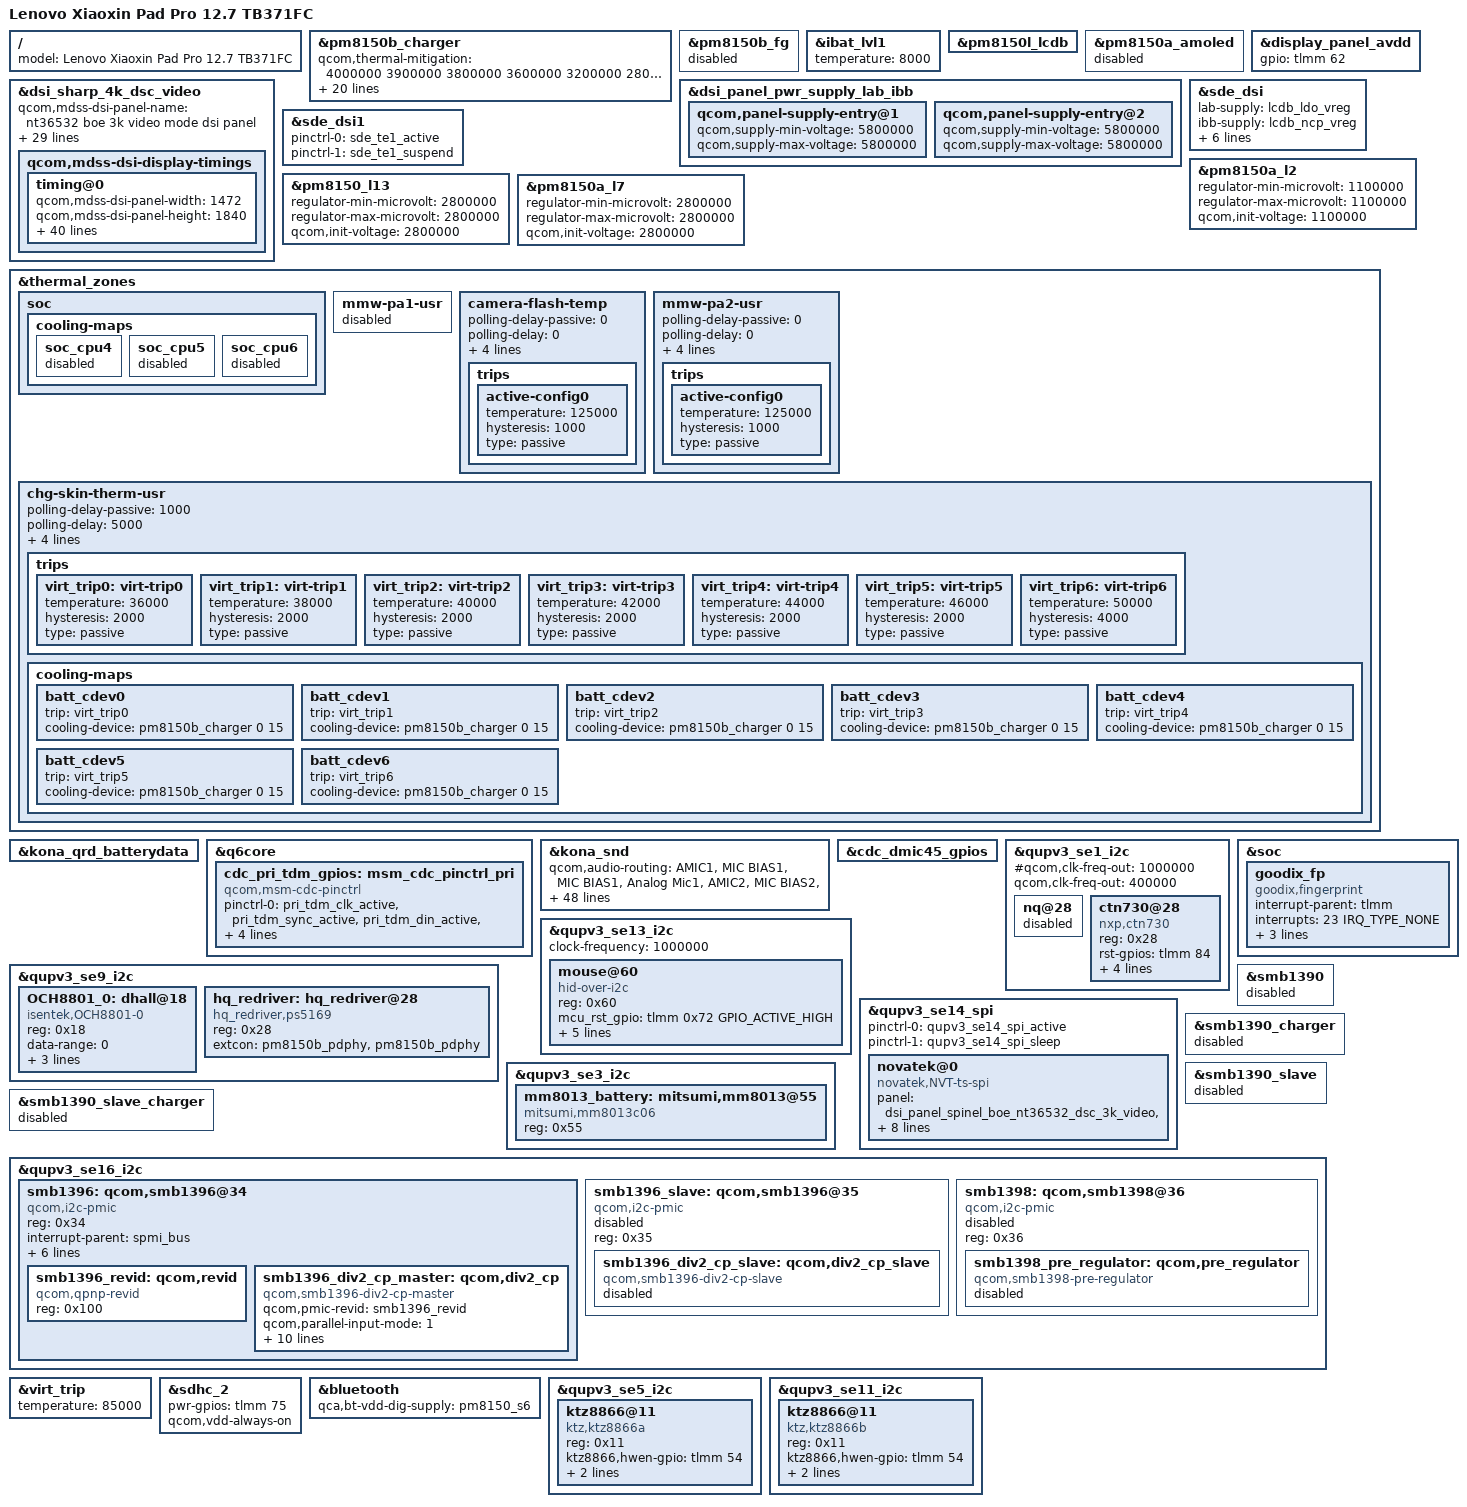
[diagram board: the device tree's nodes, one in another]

#include "kona-hdk-overlay.dts"

/ {
	model = "Lenovo Xiaoxin Pad Pro 12.7 TB371FC";
};

&pm8150b_charger {
	/delete-property/ qcom,sw-jeita-enable;
	/delete-property/ qcom,suspend-input-on-debug-batt;
	/delete-property/ qcom,fcc-stepping-enable;

	device_type = "battery";
	qcom,thermal-mitigation = <4000000 3900000 3800000 3600000 3200000 2800000 2400000 2000000 1800000 1600000 1400000 1200000 1000000 800000 600000 500000>;

	/delete-property/ qcom,auto-recharge-soc;
	qcom,auto-recharge-vbat-mv = <4380>;

	io-channels = <&pm8150b_vadc ADC_MID_CHG_DIV6>,
			 <&pm8150b_vadc ADC_USB_IN_I>,
			 <&pm8150b_vadc ADC_AMUX_THM3_PU2>,
			 <&pm8150b_vadc ADC_SBUx>,
			 <&pm8150b_vadc ADC_VPH_PWR>,
			 <&pm8150b_vadc ADC_CHG_TEMP>;
	io-channel-names = "mid_voltage", "usb_in_current", "conn_temp", "sbux_res", "vph_voltage", "chg_temp";

	qcom,pd-thermal-mitigation = <6000000 5450000 5300000 5000000 4600000 4200000 3800000 3400000 3200000 3000000 2800000 2600000 2400000 2400000 2200000 2100000>;
	qcom,chg-control-gpio = <&pm8150_gpios 10 GPIO_ACTIVE_HIGH>;
	lenovo,jeita_enable = <1>;
	qcom,fv-max-uv = <4490000>;
	qcom,fcc-max-ua = <6000000>;
	qcom,max-voltage-uv = <4490000>;
	qcom,fastchg-current-ma = <6000>;
	qcom,jeita-fcc-ranges = <0 150 3000000>,
			 <150 450 3000000>,
			 <450 500 3000000>;
	qcom,jeita-fv-ranges = <0 500 4450000>;
	qcom,otg-cl-ua = <1800000>;
	qcom,hvdcp2-max-icl-ua = <2000000>;
};

&pm8150b_fg {
	status = "disabled";
};

&ibat_lvl1 {
	temperature = <8000>;
};

&pm8150l_lcdb {
	status = "ok";
};

&pm8150a_amoled {
	status = "disabled";
};

&dsi_sharp_4k_dsc_video {
	/delete-property/ qcom,adjust-timer-wakeup-ms;
	/delete-property/ qcom,mdss-dsi-panel-hdr-enabled;
	/delete-property/ qcom,mdss-dsi-panel-hdr-color-primaries;
	/delete-property/ qcom,mdss-dsi-panel-peak-brightness;
	/delete-property/ qcom,mdss-dsi-panel-blackness-level;

	qcom,mdss-dsi-panel-name = "nt36532 boe 3k video mode dsi panel";
	qcom,mdss-dsi-lp11-init;
	qcom,mdss-dsi-underflow-color = <0xff>;
	qcom,mdss-dsi-reset-sequence = <1 10>, <0 10>, <1 10>, <0 10>, <1 10>;
	qcom,mdss-pan-physical-width-dimension = <274>;
	qcom,mdss-pan-physical-height-dimension = <171>;
	qcom,mdss-dsi-rx-eot-ignore;
	qcom,cmd-sync-wait-broadcast;
	qcom,mdss-dsi-panel-broadcast-mode;
	qcom,mdss-dsi-pan-enable-dynamic-fps;
	qcom,mdss-dsi-pan-fps-update = "dfps_immediate_porch_mode_vfp";
	qcom,dsi-supported-dfps-list = <30 60 120>;
	qcom,mdss-dsi-panel-count = <2>;
	qcom,ulps-enabled;
	qcom,esd-check-enabled;
	qcom,dsi-ctrl-num = <0 1>;
	qcom,dsi-phy-num = <0 1>;
	qcom,mdss-dsi-panel-status-check-mode = "te_signal_check";
	qcom,panel-supply-entries = <&dsi_panel_pwr_supply_lab_ibb>;
	qcom,mdss-dsi-bl-pmic-control-type = "bl_ctrl_external";
	qcom,mdss-dsi-bl-min-level = <1>;
	qcom,mdss-dsi-bl-max-level = <2047>;
	qcom,mdss-brightness-max-level = <2047>;
	qcom,platform-reset-gpio = <&tlmm 69 GPIO_ACTIVE_HIGH>;
	qcom,platform-te-gpio = <&tlmm 66 GPIO_ACTIVE_HIGH>;

	qcom,mdss-dsi-display-timings {
		timing@0 {
			qcom,mdss-dsi-panel-width = <1472>;
			qcom,mdss-dsi-panel-height = <1840>;
			qcom,mdss-dsi-h-front-porch = <201>;
			qcom,mdss-dsi-h-back-porch = <60>;
			qcom,mdss-dsi-h-pulse-width = <12>;
			qcom,mdss-dsi-v-back-porch = <182>;
			qcom,mdss-dsi-v-front-porch = <26>;
			qcom,mdss-dsi-v-pulse-width = <2>;
			qcom,mdss-dsi-panel-framerate = <120>;
			qcom,mdss-dsi-h-left-border = <0>;
			qcom,mdss-dsi-h-right-border = <0>;
			qcom,mdss-dsi-v-top-border = <0>;
			qcom,mdss-dsi-v-bottom-border = <0>;
			qcom,mdss-dsi-panel-clockrate = <1130000000>;
			qcom,mdss-dsi-on-command = [
				39 01 00 00 00 00 02 ff 20
				39 01 00 00 00 00 02 fb 01
				39 01 00 00 00 00 02 30 00
				39 01 00 00 00 00 02 ff 10
				39 01 00 00 00 00 02 fb 01
				39 01 00 00 00 00 07 3b 03 b8 1a 0a 0a 00
				39 01 00 00 00 00 02 ff 27
				39 01 00 00 00 00 02 fb 01
				39 01 00 00 00 00 02 d0 31
				39 01 00 00 00 00 02 d1 84
				39 01 00 00 00 00 02 d2 38
				39 01 00 00 00 00 02 ff 10
				39 01 00 00 00 00 02 fb 01
				39 01 00 00 00 00 02 35 00
				05 01 00 00 78 00 02 11 00
				05 01 00 00 64 00 02 29 00
			];
			qcom,mdss-dsi-off-command = [
				05 01 00 00 00 00 02 28 00
				05 01 00 00 3c 00 02 10 00
			];
			qcom,mdss-dsi-on-command-state = "dsi_lp_mode";
			qcom,mdss-dsi-off-command-state = "dsi_lp_mode";
			qcom,mdss-dsc-version = <17>;
			qcom,mdss-dsc-scr-version = <0>;
			qcom,mdss-dsc-slice-height = <20>;
			qcom,mdss-dsc-slice-width = <736>;
			qcom,mdss-dsi-dispparam-pen-144hz-command = [
				39 00 00 00 00 00 02 ff 10
				39 00 00 00 00 00 02 fb 01
				39 01 00 00 00 00 02 b3 00
			];
			qcom,mdss-dsi-dispparam-pen-120hz-command = [
				39 00 00 00 00 00 02 ff 10
				39 00 00 00 00 00 02 fb 01
				39 01 00 00 00 00 02 b3 40
			];
			qcom,mdss-dsi-dispparam-pen-60hz-command = [
				39 00 00 00 00 00 02 ff 10
				39 00 00 00 00 00 02 fb 01
				39 01 00 00 00 00 02 b3 40
			];
			qcom,mdss-dsi-dispparam-pen-30hz-command = [
				39 00 00 00 00 00 02 ff 10
				39 00 00 00 00 00 02 fb 01
				39 01 00 00 00 00 02 b3 40
			];
			qcom,mdss-dsi-dispparam-pen-144hz-command-state = "dsi_lp_mode";
			qcom,mdss-dsi-dispparam-pen-120hz-command-state = "dsi_lp_mode";
			qcom,mdss-dsi-dispparam-pen-60hz-command-state = "dsi_lp_mode";
			qcom,mdss-dsi-dispparam-pen-30hz-command-state = "dsi_lp_mode";
			qcom,mdss-dsi-panel-phy-timings = [
				00 25 0a 0a 1b 18 0a
				0a 0a 02 04 00 1f 0f
			];
		};
	};
};

&dsi_panel_pwr_supply_lab_ibb {
	qcom,panel-supply-entry@1 {
		qcom,supply-min-voltage = <5800000>;
		qcom,supply-max-voltage = <5800000>;
	};

	qcom,panel-supply-entry@2 {
		qcom,supply-min-voltage = <5800000>;
		qcom,supply-max-voltage = <5800000>;
	};
};

&display_panel_avdd {
	gpio = <&tlmm 62 0x00>;
	/delete-property/ pinctrl-names;
	/delete-property/ pinctrl-0;
};

&sde_dsi {
	lab-supply = <&lcdb_ldo_vreg>;
	ibb-supply = <&lcdb_ncp_vreg>;
	/delete-property/ vddio-supply;
	/delete-property/ vdd-supply;
	/delete-property/ avdd-supply;

	pinctrl-0 = <&sde_te_active &sde_bl_active>;
	pinctrl-1 = <&sde_te_suspend &sde_bl_suspend>;

	qcom,dsi-default-panel = <&mdss_dsi_panel_spinel_boe_nt36532_dsc_3k_video>,
				 <&mdss_dsi_panel_spinel_tianma_nt36532_dsc_3k_video>,
				 <&mdss_dsi_sharp_4k_dsc_video>;
};

&sde_dsi1 {
	pinctrl-0 = <&sde_te1_active>;
	pinctrl-1 = <&sde_te1_suspend>;
};

&pm8150a_l2 {
	regulator-min-microvolt = <1100000>;
	regulator-max-microvolt = <1100000>;
	qcom,init-voltage = <1100000>;
	status = "ok";
};

&pm8150_l13 {
	regulator-min-microvolt = <2800000>;
	regulator-max-microvolt = <2800000>;
	qcom,init-voltage = <2800000>;
	status = "ok";
};

&pm8150a_l7 {
	regulator-min-microvolt = <2800000>;
	regulator-max-microvolt = <2800000>;
	qcom,init-voltage = <2800000>;
	status = "ok";
};


/*
 * The nodes `soc_cpu4`, `soc_cpu5`, and `soc_cpu6` are absent from the
 * original DTB. Because runtime overlays cannot structurally
 * delete nodes defined by the new base DTS, these nodes are explicitly
 * disabled here to replicate the original hardware state.
 */

&thermal_zones {
	soc {
		cooling-maps {
			soc_cpu4 {
				status = "disabled";
			};
			soc_cpu5 {
				status = "disabled";
			};
			soc_cpu6 {
				status = "disabled";
			};
		};
	};
};

&kona_qrd_batterydata {
	/delete-node/ qcom,mlp466274_3650mah_averaged_masterslave_jan21st2019;
	/delete-node/ qcom,atl466274_3650mah_averaged_masterslave_may14th2019;
};

&q6core {
	cdc_pri_tdm_gpios: msm_cdc_pinctrl_pri {
		compatible = "qcom,msm-cdc-pinctrl";
		pinctrl-names = "aud_active", "aud_sleep";
		pinctrl-0 = <&pri_tdm_clk_active &pri_tdm_sync_active &pri_tdm_din_active &pri_tdm_dout_active>;
		pinctrl-1 = <&pri_tdm_clk_sleep &pri_tdm_sync_sleep &pri_tdm_din_sleep &pri_tdm_dout_sleep>;
	};
};

&kona_snd {
	qcom,audio-routing =
		"AMIC1", "MIC BIAS1", "MIC BIAS1", "Analog Mic1",
		"AMIC2", "MIC BIAS2", "MIC BIAS2", "Analog Mic2",
		"AMIC5", "MIC BIAS3", "MIC BIAS3", "Analog Mic5",
		"TX DMIC0", "MIC BIAS3", "MIC BIAS3", "Digital Mic0",
		"TX DMIC1", "MIC BIAS3", "MIC BIAS3", "Digital Mic1",
		"TX DMIC2", "MIC BIAS1", "MIC BIAS1", "Digital Mic2",
		"TX DMIC3", "MIC BIAS1", "MIC BIAS1", "Digital Mic3",
		"TX DMIC5", "MIC BIAS4", "MIC BIAS4", "Digital Mic5",
		"IN1_HPHL", "HPHL_OUT",
		"IN2_HPHR", "HPHR_OUT",
		"IN3_AUX", "AUX_OUT",
		"TX SWR_ADC0", "ADC1_OUTPUT",
		"TX SWR_ADC1", "ADC2_OUTPUT",
		"TX SWR_ADC2", "ADC3_OUTPUT",
		"TX SWR_ADC3", "ADC4_OUTPUT",
		"TX SWR_DMIC0", "DMIC1_OUTPUT",
		"TX SWR_DMIC1", "DMIC2_OUTPUT",
		"TX SWR_DMIC2", "DMIC3_OUTPUT",
		"TX SWR_DMIC3", "DMIC4_OUTPUT",
		"TX SWR_DMIC4", "DMIC5_OUTPUT",
		"TX SWR_DMIC5", "DMIC6_OUTPUT",
		"TX SWR_DMIC6", "DMIC7_OUTPUT",
		"TX SWR_DMIC7", "DMIC8_OUTPUT",
		"RX_TX DEC0_INP", "TX DEC0 MUX",
		"RX_TX DEC1_INP", "TX DEC1 MUX",
		"RX_TX DEC2_INP", "TX DEC2 MUX",
		"RX_TX DEC3_INP", "TX DEC3 MUX",
		"SpkrRight IN", "WSA_SPK2 OUT",
		"VA_AIF1 CAP", "VA_SWR_CLK",
		"VA_AIF2 CAP", "VA_SWR_CLK",
		"VA_AIF3 CAP", "VA_SWR_CLK",
		"VA MIC BIAS3", "Digital Mic0",
		"VA MIC BIAS3", "Digital Mic1",
		"VA MIC BIAS1", "Digital Mic2",
		"VA MIC BIAS1", "Digital Mic3",
		"VA MIC BIAS4", "Digital Mic5",
		"VA DMIC0", "VA MIC BIAS3",
		"VA DMIC1", "VA MIC BIAS3",
		"VA DMIC2", "VA MIC BIAS1",
		"VA DMIC3", "VA MIC BIAS1",
		"VA DMIC5", "VA MIC BIAS4",
		"VA SWR_ADC1", "VA_SWR_CLK",
		"VA SWR_MIC0", "VA_SWR_CLK",
		"VA SWR_MIC1", "VA_SWR_CLK",
		"VA SWR_MIC2", "VA_SWR_CLK",
		"VA SWR_MIC3", "VA_SWR_CLK",
		"VA SWR_MIC4", "VA_SWR_CLK",
		"VA SWR_MIC5", "VA_SWR_CLK",
		"VA SWR_MIC6", "VA_SWR_CLK",
		"VA SWR_MIC7", "VA_SWR_CLK",
		"VA SWR_MIC0", "DMIC1_OUTPUT",
		"VA SWR_MIC1", "DMIC2_OUTPUT",
		"VA SWR_MIC2", "DMIC3_OUTPUT",
		"VA SWR_MIC3", "DMIC4_OUTPUT",
		"VA SWR_MIC4", "DMIC5_OUTPUT",
		"VA SWR_MIC5", "DMIC6_OUTPUT",
		"VA SWR_MIC6", "DMIC7_OUTPUT",
		"VA SWR_MIC7", "DMIC8_OUTPUT",
		"VA SWR_ADC1", "ADC2_OUTPUT";

	qcom,tdm-max-slots = <4>;
	qcom,pri-mi2s-gpios = <&cdc_pri_tdm_gpios>;

	/*
	 * Note: `/delete-property/` is not supported in dynamic DTBOs
	 * processed by the bootloader. To match the original DTB, these properties
	 * are instead overridden with empty values (<> or ""), neutralizing them
	 * so the driver skips them.
	 */

	qcom,wsa-max-devs = <0>;
	qcom,wsa-devs = <>;
	qcom,wsa-aux-dev-prefix = "";

	qcom,tert-mi2s-gpios = <>;
};

&cdc_dmic45_gpios {
    /delete-property/ qcom,tlmm-gpio;
};

&qupv3_se1_i2c {
	status = "ok";

	/*
	 * The original DTB property is prefixed with `#`, like `#qcom,clk-freq-out`.
	 * This may indicate an attempt to comment out the property.
	 */

	#qcom,clk-freq-out = <1000000>;

	/* The driver defaults the value if the property is not found:
	 * ```
	 * 	if (of_property_read_u32(pdev->dev.of_node, "qcom,clk-freq-out",
	 *			&gi2c->i2c_rsc.clk_freq_out)) {
	 *      gi2c->i2c_rsc.clk_freq_out = KHz(400);
	 *	}
	 * ```
	 *
	 * Redefine it to such value.
	 */

	qcom,clk-freq-out = <400000>;

	#address-cells = <1>;
	#size-cells = <0>;

	nq@28 {
		status = "disabled";
	};

	ctn730@28 {
		compatible = "nxp,ctn730";
		reg = <0x28>;
		rst-gpios = <&tlmm 84 GPIO_ACTIVE_HIGH>;
		enable-gpios = <&tlmm 160 GPIO_ACTIVE_HIGH>;
		interrupt-gpios = <&tlmm 111 GPIO_ACTIVE_HIGH>;
		interrupt-parent = <&tlmm>;
		interrupts = <&l_bcl_lvl1 IRQ_TYPE_NONE>;
		interrupt-names = "nfc_irq";
	};
};

&qupv3_se9_i2c {
	status = "okay";

	OCH8801_0: dhall@18 {
		status = "okay";
		compatible = "isentek,OCH8801-0";
		reg = <0x18>;
		data-range = <0>;
		hall,bias_support = <0>;
		hall,bias-ratio = <90>;
		hall,irq-gpio = <&tlmm 0x9e GPIO_ACTIVE_HIGH>;
	};
};

&qupv3_se13_i2c {
	clock-frequency = <1000000>;
	status = "okay";

	mouse@60 {
		compatible = "hid-over-i2c";
		reg = <0x60>;
		mcu_rst_gpio = <&tlmm 0x72 GPIO_ACTIVE_HIGH>;
		mcu_resume_gpio = <&tlmm 0x6c GPIO_ACTIVE_HIGH>;
		interrupt-parent = <&tlmm>;
		interrupts = <0x6e IRQ_TYPE_NONE>;
		interrupt-names = "keyboard_irq";
		hid-descr-addr = <0x1>;
		post-power-on-delay-ms = <100>;
	};
};


&qupv3_se14_spi {
	#address-cells = <1>;
	#size-cells = <0>;
	status = "ok";
	pinctrl-0 = <&qupv3_se14_spi_active>;
	pinctrl-1 = <&qupv3_se14_spi_sleep>;

	novatek@0 {
		compatible = "novatek,NVT-ts-spi";
		panel = <&dsi_panel_spinel_boe_nt36532_dsc_3k_video>, <&dsi_panel_spinel_tianma_nt36532_dsc_3k_video>;
		reg = <0x00>;
		status = "ok";
		spi-max-frequency = <9600000>;
		novatek,reset-gpio = <&tlmm 56 IRQ_TYPE_NONE>;
		/*
		 * The value `0x2001` is used as follows in the driver context:
		 * ```
		 * 	ts->irq_gpio = of_get_named_gpio_flags(np, "novatek,irq-gpio", 0, &ts->irq_flags);
		 * ```
		 * but `irq_flags` usage is not seen anywhere
		 */
		novatek,irq-gpio = <&tlmm 68 0x2001>;
		novatek,pen-support;
		novatek,stylus-resol-double;
		novatek,mp-support-dt;

		#include "novatek-mp-criteria-6067.dtsi"
		#include "novatek-mp-criteria-6068.dtsi"
	};
};

&soc {
	goodix_fp {
		status = "okay";
		compatible = "goodix,fingerprint";
		interrupt-parent = <&tlmm>;
		interrupts = <23 IRQ_TYPE_NONE>;
		fp-gpio-irq = <&tlmm 23 GPIO_ACTIVE_HIGH>;
		fp-gpio-reset = <&tlmm 85 GPIO_ACTIVE_HIGH>;
		goodix_vdd-supply = <&pm8150a_l11>;
	};
};

&qupv3_se3_i2c {
	#address-cells = <1>;
	#size-cells = <0>;
	status = "ok";

	mm8013_battery: mitsumi,mm8013@55 {
		compatible = "mitsumi,mm8013c06";
		reg = <0x55>;
		#address-cells = <1>;
		#size-cells = <0>;
		status = "ok";
	};
};

&smb1390 {
    status = "disabled";
};

&smb1390_charger {
    status = "disabled";
};

&smb1390_slave {
    status = "disabled";
};

&smb1390_slave_charger {
    status = "disabled";
};

&qupv3_se9_i2c {
	#address-cells = <1>;
	#size-cells = <0>;
	status = "ok";

	hq_redriver: hq_redriver@28 {
		compatible = "hq_redriver,ps5169";
		reg = <0x28>;
		extcon = <&pm8150b_pdphy>, <&pm8150b_pdphy>;
	};
};

&qupv3_se16_i2c {
	#address-cells = <1>;
	#size-cells = <0>;
	status = "ok";

	smb1396: qcom,smb1396@34 {
		compatible = "qcom,i2c-pmic";
		reg = <0x34>;
		#address-cells = <1>;
		#size-cells = <0>;
		interrupt-parent = <&spmi_bus>;
		interrupts = <0x2 0xc5 0x0 IRQ_TYPE_LEVEL_LOW>;
		interrupt_names = "smb1396";
		interrupt-controller;
		#interrupt-cells = <3>;
		qcom,periph-map = <0x6 0x26 0x27>;
		status = "ok";
		pinctrl-names = "default";
		qcom,enable-toggle-stat;
		pinctrl-0 = <&smb_stat_default>;

		smb1396_revid: qcom,revid {
			compatible = "qcom,qpnp-revid";
			reg = <0x100>;
		};

		smb1396_div2_cp_master: qcom,div2_cp {
			compatible = "qcom,smb1396-div2-cp-master";
			qcom,pmic-revid = <&smb1396_revid>;
			qcom,parallel-input-mode = <1>;
			qcom,parallel-output-mode = <2>;
			qcom,div2-cp-min-ilim-ua = <750000>;
			io-channels = <&pm8150b_vadc ADC_AMUX_THM2>;
			io-channel-names = "die_temp";
			interrupts = <0x26 0x01 IRQ_TYPE_EDGE_RISING>,
					 <0x26 0x03 IRQ_TYPE_EDGE_RISING>,
					 <0x26 0x05 IRQ_TYPE_EDGE_RISING>,
					 <0x26 0x07 IRQ_TYPE_EDGE_RISING>,
					 <0x27 0x05 IRQ_TYPE_EDGE_RISING>,
					 <0x27 0x06 IRQ_TYPE_EDGE_RISING>,
					 <0x27 0x07 IRQ_TYPE_EDGE_RISING>;
			interrupt-names = "temp-shdwn",
					  "div2-irev",
					  "usbin-uv",
					  "usbin-ov",
					  "div2-ilim",
					  "div2-win-uv",
					  "div2-win-ov";
			status = "ok";
		};
	};

	smb1396_slave: qcom,smb1396@35 {
		compatible = "qcom,i2c-pmic";
		reg = <0x35>;
		#address-cells = <1>;
		#size-cells = <0>;
		status = "disabled";

		smb1396_div2_cp_slave: qcom,div2_cp_slave {
			compatible = "qcom,smb1396-div2-cp-slave";
			status = "disabled";
		};
	};

	smb1398: qcom,smb1398@36 {
		compatible = "qcom,i2c-pmic";
		reg = <0x36>;
		#address-cells = <1>;
		#size-cells = <0>;
		status = "disabled";

		smb1398_pre_regulator: qcom,pre_regulator {
			compatible = "qcom,smb1398-pre-regulator";
			status = "disabled";
		};
	};
};


&thermal_zones {
    /*
     * The node containing `thermal-sensors = <&pm8150_adc_tm ADC_AMUX_THM2_PU2>`
     * named as `mmw-pa1-usr` in the base,
     * but `camera-flash-temp` in the original DTB.
     *
     * Disabling the `mmw-pa1-usr`,
     * then redefine with the `camera-flash-temp` name.
     */

	mmw-pa1-usr {
	    status = "disabled";
	};

	camera-flash-temp {
		polling-delay-passive = <0>;
		polling-delay = <0>;
		thermal-governor = "user_space";
		thermal-sensors = <&pm8150_adc_tm ADC_AMUX_THM2_PU2>;
		wake-capable-sensor;

		trips {
			active-config0 {
				temperature = <125000>;
				hysteresis = <1000>;
				type = "passive";
			};
		};
	};

    mmw-pa2-usr {
		polling-delay-passive = <0>;
		polling-delay = <0>;
		thermal-governor = "user_space";
		thermal-sensors = <&pm8150l_adc_tm ADC_AMUX_THM3_PU2>;
		wake-capable-sensor;

		trips {

			active-config0 {
				temperature = <125000>;
				hysteresis = <1000>;
				type = "passive";
			};
		};
	};

	chg-skin-therm-usr {
		polling-delay-passive = <1000>;
		polling-delay = <5000>;
		thermal-governor = "user_space";
		thermal-sensors = <&pm8150l_adc_tm ADC_AMUX_THM3_PU2>;
		wake-capable-sensor;

		trips {

			virt_trip0: virt-trip0 {
				temperature = <36000>;
				hysteresis = <2000>;
				type = "passive";
			};

			virt_trip1: virt-trip1 {
				temperature = <38000>;
				hysteresis = <2000>;
				type = "passive";
			};

			virt_trip2: virt-trip2 {
				temperature = <40000>;
				hysteresis = <2000>;
				type = "passive";
			};

			virt_trip3: virt-trip3 {
				temperature = <42000>;
				hysteresis = <2000>;
				type = "passive";
			};

			virt_trip4: virt-trip4 {
				temperature = <44000>;
				hysteresis = <2000>;
				type = "passive";
			};

			virt_trip5: virt-trip5 {
				temperature = <46000>;
				hysteresis = <2000>;
				type = "passive";
			};

			virt_trip6: virt-trip6 {
				temperature = <50000>;
				hysteresis = <4000>;
				type = "passive";
			};
		};

		cooling-maps {

			batt_cdev0 {
				trip = <&virt_trip0>;
				cooling-device = <&pm8150b_charger 0 15>;
			};

			batt_cdev1 {
				trip = <&virt_trip1>;
				cooling-device = <&pm8150b_charger 0 15>;
			};

			batt_cdev2 {
				trip = <&virt_trip2>;
				cooling-device = <&pm8150b_charger 0 15>;
			};

			batt_cdev3 {
				trip = <&virt_trip3>;
				cooling-device = <&pm8150b_charger 0 15>;
			};

			batt_cdev4 {
				trip = <&virt_trip4>;
				cooling-device = <&pm8150b_charger 0 15>;
			};

			batt_cdev5 {
				trip = <&virt_trip5>;
				cooling-device = <&pm8150b_charger 0 15>;
			};

			batt_cdev6 {
				trip = <&virt_trip6>;
				cooling-device = <&pm8150b_charger 0 15>;
			};
		};
	};
};

&virt_trip {
    temperature = <85000>;
};

&sdhc_2 {
	pwr-gpios = <&tlmm 75 GPIO_ACTIVE_HIGH>;
	qcom,vdd-always-on;
};

&bluetooth {
	qca,bt-vdd-dig-supply = <&pm8150_s6>;
};

&qupv3_se5_i2c {
	status = "ok";

	ktz8866@11 {
		compatible = "ktz,ktz8866a";
		status = "ok";
		reg = <0x11>;
		ktz8866,hwen-gpio = <&tlmm 54 GPIO_ACTIVE_HIGH>;
		ktz8866,enp-gpio = <&tlmm 77 GPIO_ACTIVE_HIGH>;
		ktz8866,enn-gpio = <&tlmm 78 GPIO_ACTIVE_HIGH>;
	};
};

&qupv3_se11_i2c {
	status = "ok";

	ktz8866@11 {
		compatible = "ktz,ktz8866b";
		status = "ok";
		reg = <0x11>;
		ktz8866,hwen-gpio = <&tlmm 54 GPIO_ACTIVE_HIGH>;
		ktz8866,enp-gpio = <&tlmm 77 GPIO_ACTIVE_HIGH>;
		ktz8866,enn-gpio = <&tlmm 78 GPIO_ACTIVE_HIGH>;
	};
};
